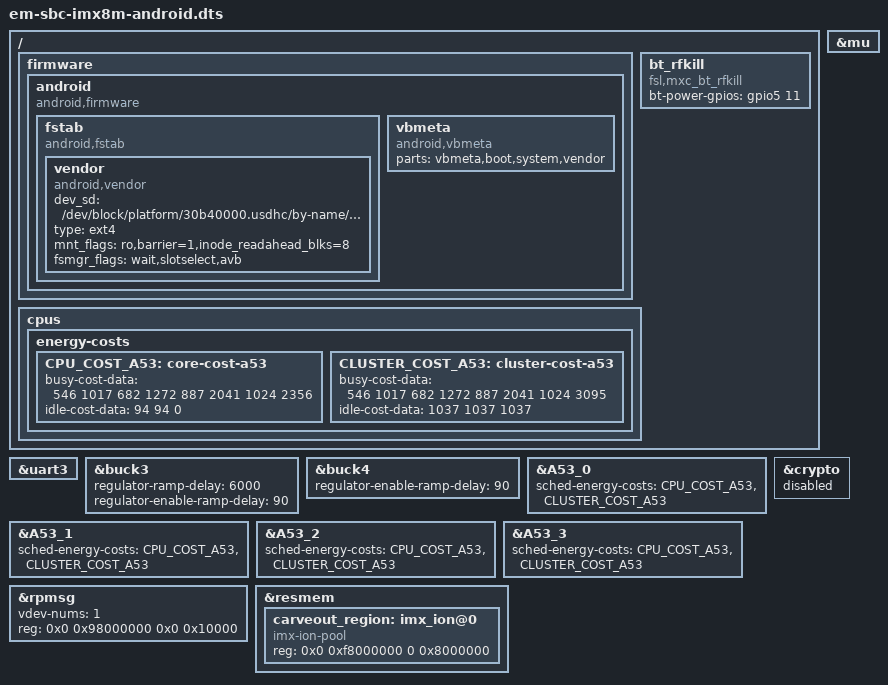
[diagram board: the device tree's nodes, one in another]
/*
 * Copyright 2019 EMBEST
 *
 * This program is free software; you can redistribute it and/or
 * modify it under the terms of the GNU General Public License
 * as published by the Free Software Foundation; either version 2
 * of the License, or (at your option) any later version.
 *
 * This program is distributed in the hope that it will be useful,
 * but WITHOUT ANY WARRANTY; without even the implied warranty of
 * MERCHANTABILITY or FITNESS FOR A PARTICULAR PURPOSE.  See the
 * GNU General Public License for more details.
 */

#include "em-sbc-imx8m.dts"

/delete-node/ &bt_reset;

/ {
	firmware {
		android {
			compatible = "android,firmware";
			fstab {
				compatible = "android,fstab";
				vendor {
					compatible = "android,vendor";
					/* sd card node which used if androidboot.storage_type=sd */
					dev_sd = "/dev/block/platform/30b40000.usdhc/by-name/vendor";
					/* emmc node which used if androidboot.storage_type=emmc */
					/* dev_emmc = "/dev/block/platform/30b40000.usdhc/by-name/vendor"; */
					type = "ext4";
					mnt_flags = "ro,barrier=1,inode_readahead_blks=8";
					fsmgr_flags = "wait,slotselect,avb";
				};
			};
			vbmeta {
				/*we need use FirstStageMountVBootV2 if we enable avb*/
				compatible = "android,vbmeta";
				/*parts means the partition witch can be mount in first stage*/
				parts = "vbmeta,boot,system,vendor";
			};
		};
	};

	bt_rfkill {
		compatible = "fsl,mxc_bt_rfkill";
		bt-power-gpios = <&gpio5 11 GPIO_ACTIVE_HIGH>; /* BT_REG_ON */
		status ="okay";
	};

};

&uart3 { /* BT */
	/delete-property/ resets;
};

&buck3 {
		regulator-ramp-delay = <6000>;
		regulator-enable-ramp-delay= <90>;
};

&buck4 {
		regulator-enable-ramp-delay= <90>;
};

/* Data for energy-aware-scheduling */
/{
	cpus {
		energy-costs {
			CPU_COST_A53: core-cost-a53 {
				busy-cost-data = <
					546  1017
					682  1272
					887  2041
					1024 2356
				>;
				idle-cost-data = <
					94
					94
					0
				>;
			};
			CLUSTER_COST_A53: cluster-cost-a53 {
				busy-cost-data = <
					546  1017
					682  1272
					887  2041
					1024 3095
				>;
				idle-cost-data = <
					1037
					1037
					1037
				>;
			};
		};
	};
};

&A53_0 {
	sched-energy-costs = <&CPU_COST_A53 &CLUSTER_COST_A53>;
};
&A53_1 {
	sched-energy-costs = <&CPU_COST_A53 &CLUSTER_COST_A53>;
};
&A53_2 {
	sched-energy-costs = <&CPU_COST_A53 &CLUSTER_COST_A53>;
};
&A53_3 {
	sched-energy-costs = <&CPU_COST_A53 &CLUSTER_COST_A53>;
};


&mu {
	status = "okay";
};

&rpmsg{
	/*
	 * 64K for one rpmsg instance:
	 * --0x98000000~0x9800ffff: pingpong
	 */
	vdev-nums = <1>;
	reg = <0x0 0x98000000 0x0 0x10000>;
	status = "okay";
};

&crypto {
       status = "disabled";
};

&resmem {
	carveout_region: imx_ion@0 {
		compatible = "imx-ion-pool";
		reg = <0x0 0xf8000000 0 0x8000000>;
	};
};
